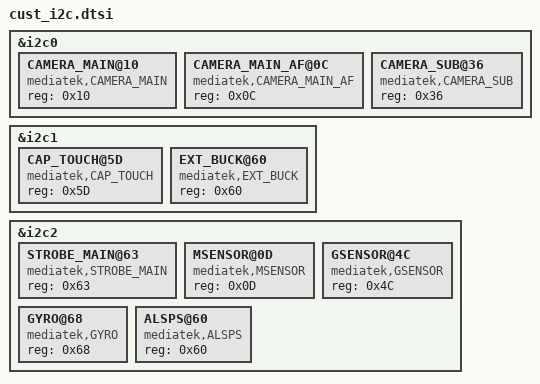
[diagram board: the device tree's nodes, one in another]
/*
 * Generated by MTK SP DrvGen Version 03.13.6 for MT6580. Copyright MediaTek Inc. (C) 2013.
 * Thu Dec 13 18:34:51 2018
 * Do Not Modify the File.
 */

/*************************
 * I2C DTSI File
*************************/

&i2c0 {
	CAMERA_MAIN@10 {
		compatible = "mediatek,CAMERA_MAIN";
		reg = <0x10>;
	};

	CAMERA_MAIN_AF@0C {
		compatible = "mediatek,CAMERA_MAIN_AF";
		reg = <0x0C>;
	};

	CAMERA_SUB@36 {
		compatible = "mediatek,CAMERA_SUB";
		reg = <0x36>;
	};

};

&i2c1 {
	CAP_TOUCH@5D {
		compatible = "mediatek,CAP_TOUCH";
		reg = <0x5D>;
	};

	EXT_BUCK@60 {
		compatible = "mediatek,EXT_BUCK";
		reg = <0x60>;
	};

};

&i2c2 {
	STROBE_MAIN@63 {
		compatible = "mediatek,STROBE_MAIN";
		reg = <0x63>;
	};

	MSENSOR@0D {
		compatible = "mediatek,MSENSOR";
		reg = <0x0D>;
	};

	GSENSOR@4C {
		compatible = "mediatek,GSENSOR";
		reg = <0x4C>;
	};

	GYRO@68 {
		compatible = "mediatek,GYRO";
		reg = <0x68>;
	};

	ALSPS@60 {
		compatible = "mediatek,ALSPS";
		reg = <0x60>;
	};

};

